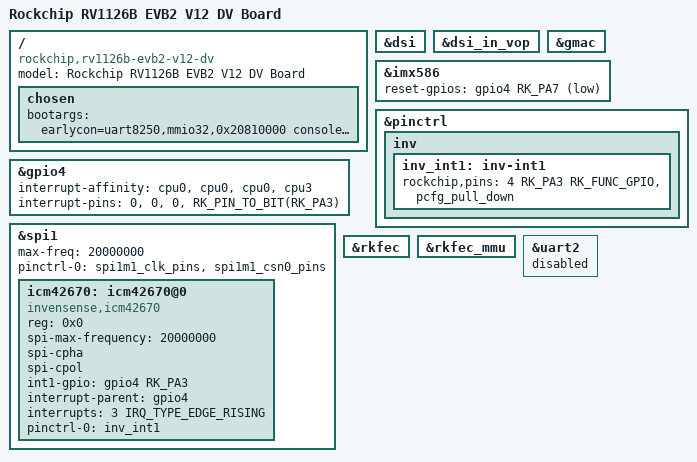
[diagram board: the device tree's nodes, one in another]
// SPDX-License-Identifier: (GPL-2.0+ OR MIT)
/*
 * Copyright (c) 2025 Rockchip Electronics Co., Ltd.
 */

/dts-v1/;
#include "rv1126b-evb2-v12.dts"

/ {
	model = "Rockchip RV1126B EVB2 V12 DV Board";
	compatible = "rockchip,rv1126b-evb2-v12-dv", "rockchip,rv1126b";
	chosen {
		bootargs = "earlycon=uart8250,mmio32,0x20810000 console=ttyFIQ0 rw root=PARTUUID=614e0000-0000 rootfstype=ext4 rootwait snd_soc_core.prealloc_buffer_size_kbytes=16 coherent_pool=32K isolcpus=3 nohz_full=3";
	};
};

&dsi {
	status = "okay";
};

&dsi_in_vop {
	status = "okay";
};

&gmac {
	status = "okay";
};

&gpio4 {
	interrupt-affinity = <&cpu0>, <&cpu0>, <&cpu0>, <&cpu3>;
	interrupt-pins = <0>,
			 <0>,
			 <0>,
			 <RK_PIN_TO_BIT(RK_PA3)>;
};

&imx586 {
	reset-gpios = <&gpio4 RK_PA7 GPIO_ACTIVE_LOW>;
};

&pinctrl {
	inv {
		inv_int1: inv-int1 {
			rockchip,pins =
				<4 RK_PA3 RK_FUNC_GPIO &pcfg_pull_down>;
		};
	};
};

&spi1 {
	status = "okay";
	max-freq = <20000000>;
	pinctrl-names = "default";
	pinctrl-0 = <&spi1m1_clk_pins &spi1m1_csn0_pins>;
	icm42670: icm42670@0 {
		compatible = "invensense,icm42670";
		reg = <0x0>;
		spi-max-frequency = <20000000>;
		spi-cpha;
		spi-cpol;
		int1-gpio = <&gpio4 RK_PA3 GPIO_ACTIVE_HIGH>;
		interrupt-parent = <&gpio4>;
		interrupts = <3 IRQ_TYPE_EDGE_RISING>;
		pinctrl-names = "default";
		pinctrl-0 = <&inv_int1>;
		status = "okay";
	};
};

&rkfec {
	status = "okay";
};

&rkfec_mmu {
	status = "okay";
};

&uart2 {
	status = "disabled";
};
